# CY8C5888LTI_LP097 register map
File version: 0.1
CY8C58LP
Registers are 8-bit, read-write, no defined reset value unless marked. A register's access mark holds for its fields unless they carry their own. Offsets are from the block's base; lines under a group give offsets from that group; [hi:lo] are bit positions; {n}, {i} and the like mark numbered series; 'fields as' and 'values as' point back to an identical list; <NAME> marks a mode.

## Memory map
0x00000000 ADC_SAR_2 — SAR ADC
0x00000000 PIXEL
0x00000000 ADC_SAR_1 — SAR ADC
0x00000000 UART
0x00000000 HORIZ
0x00000000 VERT
0x00000000 HSYNC
0x00000000 VSYNC

## ADC_SAR_2 — SAR ADC
Base 0x00000000
0x40004616 SAR_TR0 — SAR trim register
{0x40005908+i} SAR_CSR{i} (i=0..6) — SAR status and control register {i}
0x40005B28 SAR_SW0 — SAR Analog Routing Register 0
{0x40005B28+i} SAR_SW{i} (i=2..4) — SAR Analog Routing Register {i}
0x40005B2E SAR_SW6 — SAR Analog Routing Register 6
0x40005B2F SAR_CLK — SAR Clock Selection Register
0x40005BA2 SAR_WRK 16-bit — SAR working register

## PIXEL
Base 0x00000000
0x40006577 PIXEL_CONTROL_REG

## ADC_SAR_1 — SAR ADC
Base 0x00000000
0x40004614 SAR_TR0 — SAR trim register
{0x40005900+i} SAR_CSR{i} (i=0..6) — SAR status and control register {i}
0x40005B20 SAR_SW0 — SAR Analog Routing Register 0
{0x40005B20+i} SAR_SW{i} (i=2..4) — SAR Analog Routing Register {i}
0x40005B26 SAR_SW6 — SAR Analog Routing Register 6
0x40005B27 SAR_CLK — SAR Clock Selection Register
0x40005BA0 SAR_WRK 16-bit — SAR working register

## UART
Base 0x00000000
0x40006446 TX_UART_TX_DATA — TX Data Register
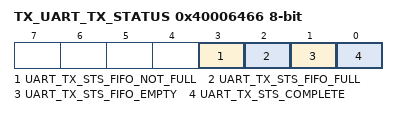
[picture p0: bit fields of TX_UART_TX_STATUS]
0x40006466 TX_UART_TX_STATUS — TX status register
  [3] UART_TX_STS_FIFO_NOT_FULL ro, [2] UART_TX_STS_FIFO_FULL ro, [1] UART_TX_STS_FIFO_EMPTY ro, [0] UART_TX_STS_COMPLETE ro

## HORIZ
Base 0x00000000
0x40006525 HORIZ__COMPARE1 — UDB.D0 - Assigned Compare1 Value
0x40006535 HORIZ__COMPARE2 — UDB.D1 - Assigned Compare2 Value
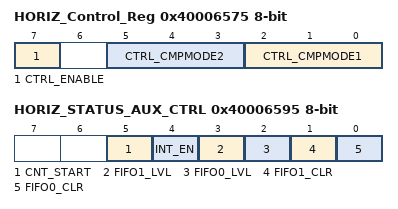
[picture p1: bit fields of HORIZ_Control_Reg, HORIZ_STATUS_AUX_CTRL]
0x40006575 HORIZ_Control_Reg — UDB Control Register - Assigned Control Register Value
  [7] CTRL_ENABLE — Enable the PWM
  [5:3] CTRL_CMPMODE2 — Compare mode 2
  [2:0] CTRL_CMPMODE1 — Compare mode 1
0x40006595 HORIZ_STATUS_AUX_CTRL — UDB Auxilliary Control Register
  [5] CNT_START — FIFO0 clear
    0=E_CNT_START0 (Disable counter); 1=E_CNT_START1 (Enable counter)
  [4] INT_EN
    0=E_INT_EN0 (Interrupt disabled); 1=E_INT_EN1 (Interrupt enabled)
  [3] FIFO1_LVL — FIFO level
    0=E_FIFO_LVL_0 (FIFO LVL: input mode: FIFO not full; output mode: FIFO not empty); 1=E_FIFO_LVL_1 (FIFO LVL: input mode: FIFO at least 1/2 empty; output mode: FIFO at least 1/2 full)
  [2] FIFO0_LVL — FIFO level
    values as FIFO1_LVL
  [1] FIFO1_CLR — FIFO1 clear
    0=E_FIFO_CLR_0 (Normal FIFO operation); 1=E_FIFO_CLR_1 (Clear FIFO state)
  [0] FIFO0_CLR — FIFO0 clear
    values as FIFO1_CLR

## VERT
Base 0x00000000
0x4000652A VERT_COMPARE_Reg 16-bit — UDB.D0 - Assigned Compare Value
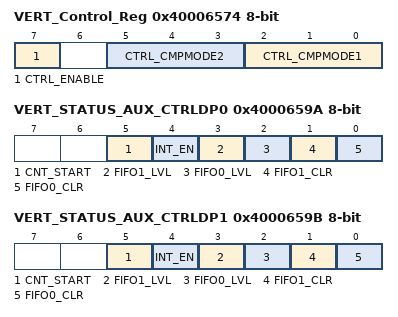
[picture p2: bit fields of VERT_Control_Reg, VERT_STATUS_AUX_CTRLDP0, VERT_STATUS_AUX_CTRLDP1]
0x40006574 VERT_Control_Reg — UDB Control Register - Assigned Control Register Value
  [7] CTRL_ENABLE — Enable the PWM
  [5:3] CTRL_CMPMODE2 — Compare mode 2
  [2:0] CTRL_CMPMODE1 — Compare mode 1
0x4000659A VERT_STATUS_AUX_CTRLDP0 — UDB Auxilliary Control Register
  fields as HORIZ.HORIZ_STATUS_AUX_CTRL
0x4000659B VERT_STATUS_AUX_CTRLDP1 — UDB Auxilliary Control Register
  fields as HORIZ.HORIZ_STATUS_AUX_CTRL

## HSYNC
Base 0x00000000
0x40006527 HSYNC_COMPARE_Reg_ — UDB.D0 - Assigned Compare Value
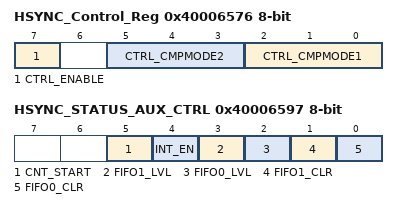
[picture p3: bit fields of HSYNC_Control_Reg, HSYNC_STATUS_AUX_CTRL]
0x40006576 HSYNC_Control_Reg — UDB Control Register - Assigned Control Register Value
  [7] CTRL_ENABLE — Enable the PWM
  [5:3] CTRL_CMPMODE2 — Compare mode 2
  [2:0] CTRL_CMPMODE1 — Compare mode 1
0x40006597 HSYNC_STATUS_AUX_CTRL — UDB Auxilliary Control Register
  fields as HORIZ.HORIZ_STATUS_AUX_CTRL

## VSYNC
Base 0x00000000
0x40006524 VSYNC_COMPARE_Reg_ — UDB.D0 - Assigned Compare Value
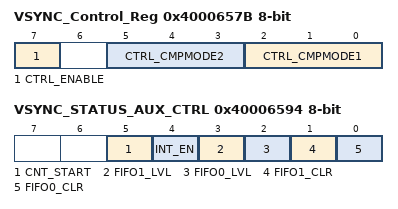
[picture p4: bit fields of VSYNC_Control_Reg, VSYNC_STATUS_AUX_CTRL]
0x4000657B VSYNC_Control_Reg — UDB Control Register - Assigned Control Register Value
  [7] CTRL_ENABLE — Enable the PWM
  [5:3] CTRL_CMPMODE2 — Compare mode 2
  [2:0] CTRL_CMPMODE1 — Compare mode 1
0x40006594 VSYNC_STATUS_AUX_CTRL — UDB Auxilliary Control Register
  fields as HORIZ.HORIZ_STATUS_AUX_CTRL
